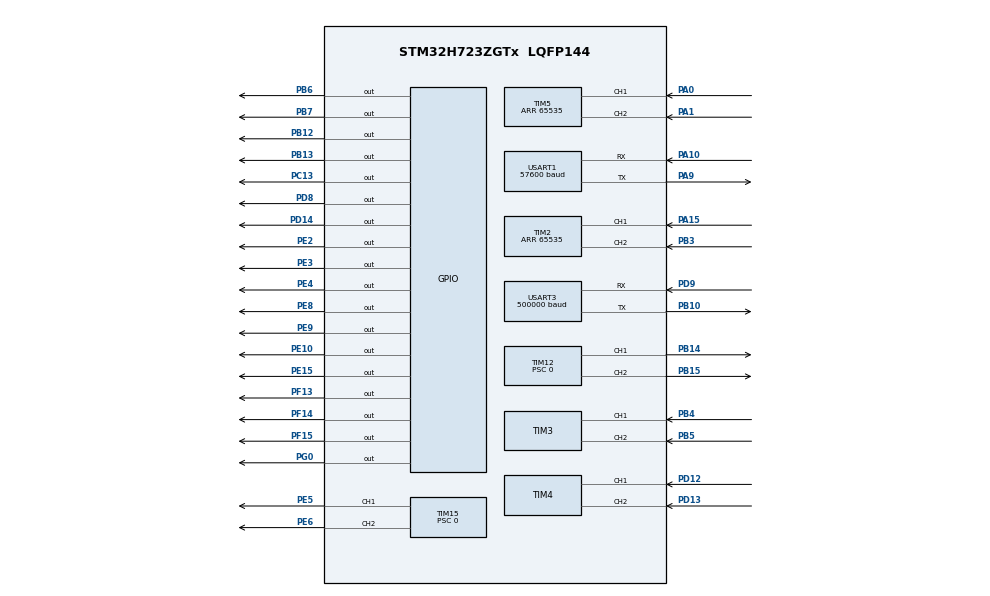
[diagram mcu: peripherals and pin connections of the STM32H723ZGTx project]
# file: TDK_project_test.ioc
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Dma.Request0=USART1_RX
Dma.Request1=USART1_TX
Dma.USART1_RX.0.Direction=DMA_PERIPH_TO_MEMORY
Dma.USART1_RX.0.EventEnable=DISABLE
Dma.USART1_RX.0.FIFOMode=DMA_FIFOMODE_DISABLE
Dma.USART1_RX.0.Instance=DMA1_Stream0
Dma.USART1_RX.0.MemDataAlignment=DMA_MDATAALIGN_BYTE
Dma.USART1_RX.0.MemInc=DMA_MINC_ENABLE
Dma.USART1_RX.0.Mode=DMA_CIRCULAR
Dma.USART1_RX.0.PeriphDataAlignment=DMA_PDATAALIGN_BYTE
Dma.USART1_RX.0.PeriphInc=DMA_PINC_DISABLE
Dma.USART1_RX.0.Polarity=HAL_DMAMUX_REQ_GEN_RISING
Dma.USART1_RX.0.Priority=DMA_PRIORITY_HIGH
Dma.USART1_RX.0.RequestNumber=1
Dma.USART1_RX.0.SignalID=NONE
Dma.USART1_RX.0.SyncEnable=DISABLE
Dma.USART1_RX.0.SyncPolarity=HAL_DMAMUX_SYNC_NO_EVENT
Dma.USART1_RX.0.SyncRequestNumber=1
Dma.USART1_RX.0.SyncSignalID=NONE
Dma.USART1_TX.1.Direction=DMA_MEMORY_TO_PERIPH
Dma.USART1_TX.1.EventEnable=DISABLE
Dma.USART1_TX.1.FIFOMode=DMA_FIFOMODE_DISABLE
Dma.USART1_TX.1.Instance=DMA1_Stream1
Dma.USART1_TX.1.MemDataAlignment=DMA_MDATAALIGN_BYTE
Dma.USART1_TX.1.MemInc=DMA_MINC_ENABLE
Dma.USART1_TX.1.Mode=DMA_NORMAL
Dma.USART1_TX.1.PeriphDataAlignment=DMA_PDATAALIGN_BYTE
Dma.USART1_TX.1.PeriphInc=DMA_PINC_DISABLE
Dma.USART1_TX.1.Polarity=HAL_DMAMUX_REQ_GEN_RISING
Dma.USART1_TX.1.Priority=DMA_PRIORITY_HIGH
Dma.USART1_TX.1.RequestNumber=1
Dma.USART1_TX.1.SignalID=NONE
Dma.USART1_TX.1.SyncEnable=DISABLE
Dma.USART1_TX.1.SyncPolarity=HAL_DMAMUX_SYNC_NO_EVENT
Dma.USART1_TX.1.SyncRequestNumber=1
Dma.USART1_TX.1.SyncSignalID=NONE
Mcu.Family=STM32H7
Mcu.Name=STM32H723ZGTx
Mcu.Package=LQFP144
NVIC.DMA1_Stream0_IRQn=true\:0\:0\:false\:false\:true\:false\:true\:true
NVIC.DMA1_Stream1_IRQn=true\:0\:0\:false\:false\:true\:false\:true\:true
NVIC.PriorityGroup=NVIC_PRIORITYGROUP_4
NVIC.TIM1_BRK_IRQn=true\:0\:0\:false\:false\:true\:true\:true\:true
NVIC.TIM1_CC_IRQn=true\:0\:0\:false\:false\:true\:true\:true\:true
NVIC.TIM1_TRG_COM_IRQn=true\:0\:0\:false\:false\:true\:true\:true\:true
NVIC.TIM1_UP_IRQn=true\:0\:0\:false\:false\:true\:true\:true\:true
NVIC.TIM23_IRQn=true\:0\:0\:false\:false\:true\:true\:true\:true
NVIC.TIM8_BRK_TIM12_IRQn=true\:0\:0\:false\:false\:true\:true\:true\:true
NVIC.TIM8_CC_IRQn=true\:0\:0\:false\:false\:true\:true\:true\:true
NVIC.TIM8_TRG_COM_TIM14_IRQn=true\:0\:0\:false\:false\:true\:true\:true\:true
NVIC.TIM8_UP_TIM13_IRQn=true\:0\:0\:false\:false\:true\:true\:true\:true
NVIC.USART1_IRQn=true\:0\:0\:false\:false\:true\:true\:true\:true
NVIC.USART3_IRQn=true\:0\:0\:false\:false\:true\:true\:true\:true
PA0.Signal=S_TIM5_CH1
PA1.Signal=S_TIM5_CH2
PA10.Mode=Asynchronous
PA10.Signal=USART1_RX
PA15(JTDI).Signal=S_TIM2_CH1_ETR
PA9.Mode=Asynchronous
PA9.Signal=USART1_TX
PB10.Mode=Asynchronous
PB10.Signal=USART3_TX
PB12.Signal=GPIO_Output
PB13.Signal=GPIO_Output
PB14.Signal=S_TIM12_CH1
PB15.Signal=S_TIM12_CH2
PB3(JTDO/TRACESWO).Signal=S_TIM2_CH2
PB4(NJTRST).Signal=S_TIM3_CH1
PB5.Signal=S_TIM3_CH2
PB6.Signal=GPIO_Output
PB7.Signal=GPIO_Output
PC13.Signal=GPIO_Output
PD12.Signal=S_TIM4_CH1
PD13.Signal=S_TIM4_CH2
PD14.Signal=GPIO_Output
PD8.Signal=GPIO_Output
PD9.Mode=Asynchronous
PD9.Signal=USART3_RX
PE10.Signal=GPIO_Output
PE15.Signal=GPIO_Output
PE2.Signal=GPIO_Output
PE3.Signal=GPIO_Output
PE4.Signal=GPIO_Output
PE5.Signal=S_TIM15_CH1
PE6.Signal=S_TIM15_CH2
PE8.Signal=GPIO_Output
PE9.Signal=GPIO_Output
PF13.Signal=GPIO_Output
PF14.Signal=GPIO_Output
PF15.Signal=GPIO_Output
PG0.Signal=GPIO_Output
PH0-OSC_IN.Mode=HSE-External-Oscillator
PH0-OSC_IN.Signal=RCC_OSC_IN
PH1-OSC_OUT.Mode=HSE-External-Oscillator
PH1-OSC_OUT.Signal=RCC_OSC_OUT
ProjectManager.HeapSize=0x200
ProjectManager.StackSize=0x400
ProjectManager.TargetToolchain=STM32CubeIDE
RCC.ADCFreq_Value=16125000
RCC.APB1Freq_Value=42000000
RCC.APB2Freq_Value=42000000
RCC.APB3Freq_Value=42000000
RCC.APB4Freq_Value=42000000
RCC.CortexFreq_Value=168000000
RCC.D1PPRE=RCC_APB3_DIV2
RCC.D2PPRE1=RCC_APB1_DIV2
RCC.D2PPRE2=RCC_APB2_DIV2
RCC.D3PPRE=RCC_APB4_DIV2
RCC.DIVM1=1
RCC.DIVN1=42
RCC.HCLKFreq_Value=84000000
RCC.HPRE=RCC_HCLK_DIV2
RCC.HSE_VALUE=8000000
RCC.PLLSourceVirtual=RCC_PLLSOURCE_HSE
RCC.SYSCLKFreq_VALUE=168000000
RCC.SYSCLKSource=RCC_SYSCLKSOURCE_PLLCLK
RCC.USBFreq_Value=168000000
SH.S_TIM12_CH1.0=TIM12_CH1,PWM Generation1 CH1
SH.S_TIM12_CH2.0=TIM12_CH2,PWM Generation2 CH2
SH.S_TIM15_CH1.0=TIM15_CH1,PWM Generation1 CH1
SH.S_TIM15_CH2.0=TIM15_CH2,PWM Generation2 CH2
SH.S_TIM2_CH1_ETR.0=TIM2_CH1,Encoder_Interface
SH.S_TIM2_CH2.0=TIM2_CH2,Encoder_Interface
SH.S_TIM3_CH1.0=TIM3_CH1,Encoder_Interface
SH.S_TIM3_CH2.0=TIM3_CH2,Encoder_Interface
SH.S_TIM4_CH1.0=TIM4_CH1,Encoder_Interface
SH.S_TIM4_CH2.0=TIM4_CH2,Encoder_Interface
SH.S_TIM5_CH1.0=TIM5_CH1,Encoder_Interface
SH.S_TIM5_CH2.0=TIM5_CH2,Encoder_Interface
TIM1.Period=3999
TIM1.Prescaler=83
TIM12.Channel-PWM\ Generation1\ CH1=TIM_CHANNEL_1
TIM12.Channel-PWM\ Generation2\ CH2=TIM_CHANNEL_2
TIM12.Period=999
TIM12.Prescaler=0
TIM15.Channel-PWM\ Generation1\ CH1=TIM_CHANNEL_1
TIM15.Channel-PWM\ Generation2\ CH2=TIM_CHANNEL_2
TIM15.Period=999
TIM15.Prescaler=0
TIM2.EncoderMode=TIM_ENCODERMODE_TI12
TIM2.Period=65535
TIM23.Period=9999
TIM23.Prescaler=83
TIM3.EncoderMode=TIM_ENCODERMODE_TI12
TIM4.EncoderMode=TIM_ENCODERMODE_TI12
TIM5.EncoderMode=TIM_ENCODERMODE_TI12
TIM5.Period=65535
TIM8.Period=999
TIM8.Prescaler=83
USART1.BaudRate=57600
USART1.VirtualMode-Asynchronous=VM_ASYNC
USART3.BaudRate=500000
USART3.VirtualMode-Asynchronous=VM_ASYNC
VP_TIM1_VS_ClockSourceINT.Mode=Internal
VP_TIM23_VS_ClockSourceINT.Mode=Internal
VP_TIM8_VS_ClockSourceINT.Mode=Internal
board=custom

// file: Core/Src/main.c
/* USER CODE BEGIN Header */
/**
  ******************************************************************************
  * @file           : main.c
  * @brief          : Main program body
  ******************************************************************************
  * @attention
  *
  * Copyright (c) 2023 STMicroelectronics.
  * All rights reserved.
  *
  * This software is licensed under terms that can be found in the LICENSE file
  * in the root directory of this software component.
  * If no LICENSE file comes with this software, it is provided AS-IS.
  *
  ******************************************************************************
  */
/* USER CODE END Header */
#include "main.h"

/* USER CODE BEGIN Includes */
#include "mainpp.h"
/* USER CODE END Includes */

TIM_HandleTypeDef htim1;
TIM_HandleTypeDef htim2;
TIM_HandleTypeDef htim3;
TIM_HandleTypeDef htim4;
TIM_HandleTypeDef htim5;
TIM_HandleTypeDef htim8;
TIM_HandleTypeDef htim12;
TIM_HandleTypeDef htim15;
TIM_HandleTypeDef htim23;

UART_HandleTypeDef huart1;
UART_HandleTypeDef huart3;
DMA_HandleTypeDef hdma_usart1_rx;
DMA_HandleTypeDef hdma_usart1_tx;

void SystemClock_Config(void);
static void MX_GPIO_Init(void);
static void MX_DMA_Init(void);
static void MX_TIM3_Init(void);
static void MX_TIM4_Init(void);
static void MX_TIM5_Init(void);
static void MX_TIM12_Init(void);
static void MX_TIM15_Init(void);
static void MX_TIM1_Init(void);
static void MX_TIM8_Init(void);
static void MX_TIM23_Init(void);
static void MX_USART1_UART_Init(void);
static void MX_TIM2_Init(void);
static void MX_USART3_UART_Init(void);
/* USER CODE BEGIN PFP */
int x = 0;
/* USER CODE END PFP */

int main(void)
{

  /* MCU Configuration--------------------------------------------------------*/

  /* Reset of all peripherals, Initializes the Flash interface and the Systick. */
  HAL_Init();

  /* Configure the system clock */
  SystemClock_Config();

  /* Initialize all configured peripherals */
  MX_GPIO_Init();
  MX_DMA_Init();
  MX_TIM3_Init();
  MX_TIM4_Init();
  MX_TIM5_Init();
  MX_TIM12_Init();
  MX_TIM15_Init();
  MX_TIM1_Init();
  MX_TIM8_Init();
  MX_TIM23_Init();
  MX_USART1_UART_Init();
  MX_TIM2_Init();
  MX_USART3_UART_Init();
  /* USER CODE BEGIN 2 */
  main_function();
  /* USER CODE END 2 */

  /* Infinite loop */
  while (1)
  {

  }
}

void SystemClock_Config(void)
{
  RCC_OscInitTypeDef RCC_OscInitStruct = {0};
  RCC_ClkInitTypeDef RCC_ClkInitStruct = {0};

  /** Supply configuration update enable
  */
  HAL_PWREx_ConfigSupply(PWR_LDO_SUPPLY);

  /** Configure the main internal regulator output voltage
  */
  __HAL_PWR_VOLTAGESCALING_CONFIG(PWR_REGULATOR_VOLTAGE_SCALE3);

  while(!__HAL_PWR_GET_FLAG(PWR_FLAG_VOSRDY)) {}

  /** Initializes the RCC Oscillators according to the specified parameters
  * in the RCC_OscInitTypeDef structure.
  */
  RCC_OscInitStruct.OscillatorType = RCC_OSCILLATORTYPE_HSE;
  RCC_OscInitStruct.HSEState = RCC_HSE_ON;
  RCC_OscInitStruct.PLL.PLLState = RCC_PLL_ON;
  RCC_OscInitStruct.PLL.PLLSource = RCC_PLLSOURCE_HSE;
  RCC_OscInitStruct.PLL.PLLM = 1;
  RCC_OscInitStruct.PLL.PLLN = 42;
  RCC_OscInitStruct.PLL.PLLP = 2;
  RCC_OscInitStruct.PLL.PLLQ = 2;
  RCC_OscInitStruct.PLL.PLLR = 2;
  RCC_OscInitStruct.PLL.PLLRGE = RCC_PLL1VCIRANGE_3;
  RCC_OscInitStruct.PLL.PLLVCOSEL = RCC_PLL1VCOWIDE;
  RCC_OscInitStruct.PLL.PLLFRACN = 0;
  if (HAL_RCC_OscConfig(&RCC_OscInitStruct) != HAL_OK)
  {
    Error_Handler();
  }

  /** Initializes the CPU, AHB and APB buses clocks
  */
  RCC_ClkInitStruct.ClockType = RCC_CLOCKTYPE_HCLK|RCC_CLOCKTYPE_SYSCLK
                              |RCC_CLOCKTYPE_PCLK1|RCC_CLOCKTYPE_PCLK2
                              |RCC_CLOCKTYPE_D3PCLK1|RCC_CLOCKTYPE_D1PCLK1;
  RCC_ClkInitStruct.SYSCLKSource = RCC_SYSCLKSOURCE_PLLCLK;
  RCC_ClkInitStruct.SYSCLKDivider = RCC_SYSCLK_DIV1;
  RCC_ClkInitStruct.AHBCLKDivider = RCC_HCLK_DIV2;
  RCC_ClkInitStruct.APB3CLKDivider = RCC_APB3_DIV2;
  RCC_ClkInitStruct.APB1CLKDivider = RCC_APB1_DIV2;
  RCC_ClkInitStruct.APB2CLKDivider = RCC_APB2_DIV2;
  RCC_ClkInitStruct.APB4CLKDivider = RCC_APB4_DIV2;

  if (HAL_RCC_ClockConfig(&RCC_ClkInitStruct, FLASH_LATENCY_2) != HAL_OK)
  {
    Error_Handler();
  }
}

static void MX_TIM1_Init(void)
{

  TIM_ClockConfigTypeDef sClockSourceConfig = {0};
  TIM_MasterConfigTypeDef sMasterConfig = {0};

  htim1.Instance = TIM1;
  htim1.Init.Prescaler = 83;
  htim1.Init.CounterMode = TIM_COUNTERMODE_UP;
  htim1.Init.Period = 3999;
  htim1.Init.ClockDivision = TIM_CLOCKDIVISION_DIV1;
  htim1.Init.RepetitionCounter = 0;
  htim1.Init.AutoReloadPreload = TIM_AUTORELOAD_PRELOAD_DISABLE;
  if (HAL_TIM_Base_Init(&htim1) != HAL_OK)
  {
    Error_Handler();
  }
  sClockSourceConfig.ClockSource = TIM_CLOCKSOURCE_INTERNAL;
  if (HAL_TIM_ConfigClockSource(&htim1, &sClockSourceConfig) != HAL_OK)
  {
    Error_Handler();
  }
  sMasterConfig.MasterOutputTrigger = TIM_TRGO_RESET;
  sMasterConfig.MasterOutputTrigger2 = TIM_TRGO2_RESET;
  sMasterConfig.MasterSlaveMode = TIM_MASTERSLAVEMODE_DISABLE;
  if (HAL_TIMEx_MasterConfigSynchronization(&htim1, &sMasterConfig) != HAL_OK)
  {
    Error_Handler();
  }

}

static void MX_TIM2_Init(void)
{

  TIM_Encoder_InitTypeDef sConfig = {0};
  TIM_MasterConfigTypeDef sMasterConfig = {0};

  htim2.Instance = TIM2;
  htim2.Init.Prescaler = 0;
  htim2.Init.CounterMode = TIM_COUNTERMODE_UP;
  htim2.Init.Period = 65535;
  htim2.Init.ClockDivision = TIM_CLOCKDIVISION_DIV1;
  htim2.Init.AutoReloadPreload = TIM_AUTORELOAD_PRELOAD_DISABLE;
  sConfig.EncoderMode = TIM_ENCODERMODE_TI12;
  sConfig.IC1Polarity = TIM_ICPOLARITY_RISING;
  sConfig.IC1Selection = TIM_ICSELECTION_DIRECTTI;
  sConfig.IC1Prescaler = TIM_ICPSC_DIV1;
  sConfig.IC1Filter = 0;
  sConfig.IC2Polarity = TIM_ICPOLARITY_RISING;
  sConfig.IC2Selection = TIM_ICSELECTION_DIRECTTI;
  sConfig.IC2Prescaler = TIM_ICPSC_DIV1;
  sConfig.IC2Filter = 0;
  if (HAL_TIM_Encoder_Init(&htim2, &sConfig) != HAL_OK)
  {
    Error_Handler();
  }
  sMasterConfig.MasterOutputTrigger = TIM_TRGO_RESET;
  sMasterConfig.MasterSlaveMode = TIM_MASTERSLAVEMODE_DISABLE;
  if (HAL_TIMEx_MasterConfigSynchronization(&htim2, &sMasterConfig) != HAL_OK)
  {
    Error_Handler();
  }

}

static void MX_TIM3_Init(void)
{

  TIM_Encoder_InitTypeDef sConfig = {0};
  TIM_MasterConfigTypeDef sMasterConfig = {0};

  htim3.Instance = TIM3;
  htim3.Init.Prescaler = 0;
  htim3.Init.CounterMode = TIM_COUNTERMODE_UP;
  htim3.Init.Period = 65535;
  htim3.Init.ClockDivision = TIM_CLOCKDIVISION_DIV1;
  htim3.Init.AutoReloadPreload = TIM_AUTORELOAD_PRELOAD_DISABLE;
  sConfig.EncoderMode = TIM_ENCODERMODE_TI12;
  sConfig.IC1Polarity = TIM_ICPOLARITY_RISING;
  sConfig.IC1Selection = TIM_ICSELECTION_DIRECTTI;
  sConfig.IC1Prescaler = TIM_ICPSC_DIV1;
  sConfig.IC1Filter = 0;
  sConfig.IC2Polarity = TIM_ICPOLARITY_RISING;
  sConfig.IC2Selection = TIM_ICSELECTION_DIRECTTI;
  sConfig.IC2Prescaler = TIM_ICPSC_DIV1;
  sConfig.IC2Filter = 0;
  if (HAL_TIM_Encoder_Init(&htim3, &sConfig) != HAL_OK)
  {
    Error_Handler();
  }
  sMasterConfig.MasterOutputTrigger = TIM_TRGO_RESET;
  sMasterConfig.MasterSlaveMode = TIM_MASTERSLAVEMODE_DISABLE;
  if (HAL_TIMEx_MasterConfigSynchronization(&htim3, &sMasterConfig) != HAL_OK)
  {
    Error_Handler();
  }

}

static void MX_TIM4_Init(void)
{

  TIM_Encoder_InitTypeDef sConfig = {0};
  TIM_MasterConfigTypeDef sMasterConfig = {0};

  htim4.Instance = TIM4;
  htim4.Init.Prescaler = 0;
  htim4.Init.CounterMode = TIM_COUNTERMODE_UP;
  htim4.Init.Period = 65535;
  htim4.Init.ClockDivision = TIM_CLOCKDIVISION_DIV1;
  htim4.Init.AutoReloadPreload = TIM_AUTORELOAD_PRELOAD_DISABLE;
  sConfig.EncoderMode = TIM_ENCODERMODE_TI12;
  sConfig.IC1Polarity = TIM_ICPOLARITY_RISING;
  sConfig.IC1Selection = TIM_ICSELECTION_DIRECTTI;
  sConfig.IC1Prescaler = TIM_ICPSC_DIV1;
  sConfig.IC1Filter = 0;
  sConfig.IC2Polarity = TIM_ICPOLARITY_RISING;
  sConfig.IC2Selection = TIM_ICSELECTION_DIRECTTI;
  sConfig.IC2Prescaler = TIM_ICPSC_DIV1;
  sConfig.IC2Filter = 0;
  if (HAL_TIM_Encoder_Init(&htim4, &sConfig) != HAL_OK)
  {
    Error_Handler();
  }
  sMasterConfig.MasterOutputTrigger = TIM_TRGO_RESET;
  sMasterConfig.MasterSlaveMode = TIM_MASTERSLAVEMODE_DISABLE;
  if (HAL_TIMEx_MasterConfigSynchronization(&htim4, &sMasterConfig) != HAL_OK)
  {
    Error_Handler();
  }

}

static void MX_TIM5_Init(void)
{

  TIM_Encoder_InitTypeDef sConfig = {0};
  TIM_MasterConfigTypeDef sMasterConfig = {0};

  htim5.Instance = TIM5;
  htim5.Init.Prescaler = 0;
  htim5.Init.CounterMode = TIM_COUNTERMODE_UP;
  htim5.Init.Period = 65535;
  htim5.Init.ClockDivision = TIM_CLOCKDIVISION_DIV1;
  htim5.Init.AutoReloadPreload = TIM_AUTORELOAD_PRELOAD_DISABLE;
  sConfig.EncoderMode = TIM_ENCODERMODE_TI12;
  sConfig.IC1Polarity = TIM_ICPOLARITY_RISING;
  sConfig.IC1Selection = TIM_ICSELECTION_DIRECTTI;
  sConfig.IC1Prescaler = TIM_ICPSC_DIV1;
  sConfig.IC1Filter = 0;
  sConfig.IC2Polarity = TIM_ICPOLARITY_RISING;
  sConfig.IC2Selection = TIM_ICSELECTION_DIRECTTI;
  sConfig.IC2Prescaler = TIM_ICPSC_DIV1;
  sConfig.IC2Filter = 0;
  if (HAL_TIM_Encoder_Init(&htim5, &sConfig) != HAL_OK)
  {
    Error_Handler();
  }
  sMasterConfig.MasterOutputTrigger = TIM_TRGO_RESET;
  sMasterConfig.MasterSlaveMode = TIM_MASTERSLAVEMODE_DISABLE;
  if (HAL_TIMEx_MasterConfigSynchronization(&htim5, &sMasterConfig) != HAL_OK)
  {
    Error_Handler();
  }

}

static void MX_TIM8_Init(void)
{

  TIM_ClockConfigTypeDef sClockSourceConfig = {0};
  TIM_MasterConfigTypeDef sMasterConfig = {0};

  htim8.Instance = TIM8;
  htim8.Init.Prescaler = 83;
  htim8.Init.CounterMode = TIM_COUNTERMODE_UP;
  htim8.Init.Period = 999;
  htim8.Init.ClockDivision = TIM_CLOCKDIVISION_DIV1;
  htim8.Init.RepetitionCounter = 0;
  htim8.Init.AutoReloadPreload = TIM_AUTORELOAD_PRELOAD_DISABLE;
  if (HAL_TIM_Base_Init(&htim8) != HAL_OK)
  {
    Error_Handler();
  }
  sClockSourceConfig.ClockSource = TIM_CLOCKSOURCE_INTERNAL;
  if (HAL_TIM_ConfigClockSource(&htim8, &sClockSourceConfig) != HAL_OK)
  {
    Error_Handler();
  }
  sMasterConfig.MasterOutputTrigger = TIM_TRGO_RESET;
  sMasterConfig.MasterOutputTrigger2 = TIM_TRGO2_RESET;
  sMasterConfig.MasterSlaveMode = TIM_MASTERSLAVEMODE_DISABLE;
  if (HAL_TIMEx_MasterConfigSynchronization(&htim8, &sMasterConfig) != HAL_OK)
  {
    Error_Handler();
  }

}

static void MX_TIM12_Init(void)
{

  TIM_MasterConfigTypeDef sMasterConfig = {0};
  TIM_OC_InitTypeDef sConfigOC = {0};

  htim12.Instance = TIM12;
  htim12.Init.Prescaler = 0;
  htim12.Init.CounterMode = TIM_COUNTERMODE_UP;
  htim12.Init.Period = 999;
  htim12.Init.ClockDivision = TIM_CLOCKDIVISION_DIV1;
  htim12.Init.AutoReloadPreload = TIM_AUTORELOAD_PRELOAD_DISABLE;
  if (HAL_TIM_PWM_Init(&htim12) != HAL_OK)
  {
    Error_Handler();
  }
  sMasterConfig.MasterOutputTrigger = TIM_TRGO_RESET;
  sMasterConfig.MasterSlaveMode = TIM_MASTERSLAVEMODE_DISABLE;
  if (HAL_TIMEx_MasterConfigSynchronization(&htim12, &sMasterConfig) != HAL_OK)
  {
    Error_Handler();
  }
  sConfigOC.OCMode = TIM_OCMODE_PWM1;
  sConfigOC.Pulse = 0;
  sConfigOC.OCPolarity = TIM_OCPOLARITY_HIGH;
  sConfigOC.OCFastMode = TIM_OCFAST_DISABLE;
  if (HAL_TIM_PWM_ConfigChannel(&htim12, &sConfigOC, TIM_CHANNEL_1) != HAL_OK)
  {
    Error_Handler();
  }
  if (HAL_TIM_PWM_ConfigChannel(&htim12, &sConfigOC, TIM_CHANNEL_2) != HAL_OK)
  {
    Error_Handler();
  }
  HAL_TIM_MspPostInit(&htim12);

}

static void MX_TIM15_Init(void)
{

  TIM_MasterConfigTypeDef sMasterConfig = {0};
  TIM_OC_InitTypeDef sConfigOC = {0};
  TIM_BreakDeadTimeConfigTypeDef sBreakDeadTimeConfig = {0};

  htim15.Instance = TIM15;
  htim15.Init.Prescaler = 0;
  htim15.Init.CounterMode = TIM_COUNTERMODE_UP;
  htim15.Init.Period = 999;
  htim15.Init.ClockDivision = TIM_CLOCKDIVISION_DIV1;
  htim15.Init.RepetitionCounter = 0;
  htim15.Init.AutoReloadPreload = TIM_AUTORELOAD_PRELOAD_DISABLE;
  if (HAL_TIM_PWM_Init(&htim15) != HAL_OK)
  {
    Error_Handler();
  }
  sMasterConfig.MasterOutputTrigger = TIM_TRGO_RESET;
  sMasterConfig.MasterSlaveMode = TIM_MASTERSLAVEMODE_DISABLE;
  if (HAL_TIMEx_MasterConfigSynchronization(&htim15, &sMasterConfig) != HAL_OK)
  {
    Error_Handler();
  }
  sConfigOC.OCMode = TIM_OCMODE_PWM1;
  sConfigOC.Pulse = 0;
  sConfigOC.OCPolarity = TIM_OCPOLARITY_HIGH;
  sConfigOC.OCNPolarity = TIM_OCNPOLARITY_HIGH;
  sConfigOC.OCFastMode = TIM_OCFAST_DISABLE;
  sConfigOC.OCIdleState = TIM_OCIDLESTATE_RESET;
  sConfigOC.OCNIdleState = TIM_OCNIDLESTATE_RESET;
  if (HAL_TIM_PWM_ConfigChannel(&htim15, &sConfigOC, TIM_CHANNEL_1) != HAL_OK)
  {
    Error_Handler();
  }
  if (HAL_TIM_PWM_ConfigChannel(&htim15, &sConfigOC, TIM_CHANNEL_2) != HAL_OK)
  {
    Error_Handler();
  }
  sBreakDeadTimeConfig.OffStateRunMode = TIM_OSSR_DISABLE;
  sBreakDeadTimeConfig.OffStateIDLEMode = TIM_OSSI_DISABLE;
  sBreakDeadTimeConfig.LockLevel = TIM_LOCKLEVEL_OFF;
  sBreakDeadTimeConfig.DeadTime = 0;
  sBreakDeadTimeConfig.BreakState = TIM_BREAK_DISABLE;
  sBreakDeadTimeConfig.BreakPolarity = TIM_BREAKPOLARITY_HIGH;
  sBreakDeadTimeConfig.BreakFilter = 0;
  sBreakDeadTimeConfig.AutomaticOutput = TIM_AUTOMATICOUTPUT_DISABLE;
  if (HAL_TIMEx_ConfigBreakDeadTime(&htim15, &sBreakDeadTimeConfig) != HAL_OK)
  {
    Error_Handler();
  }
  HAL_TIM_MspPostInit(&htim15);

}

static void MX_TIM23_Init(void)
{

  TIM_ClockConfigTypeDef sClockSourceConfig = {0};
  TIM_MasterConfigTypeDef sMasterConfig = {0};

  htim23.Instance = TIM23;
  htim23.Init.Prescaler = 83;
  htim23.Init.CounterMode = TIM_COUNTERMODE_UP;
  htim23.Init.Period = 9999;
  htim23.Init.ClockDivision = TIM_CLOCKDIVISION_DIV1;
  htim23.Init.AutoReloadPreload = TIM_AUTORELOAD_PRELOAD_DISABLE;
  if (HAL_TIM_Base_Init(&htim23) != HAL_OK)
  {
    Error_Handler();
  }
  sClockSourceConfig.ClockSource = TIM_CLOCKSOURCE_INTERNAL;
  if (HAL_TIM_ConfigClockSource(&htim23, &sClockSourceConfig) != HAL_OK)
  {
    Error_Handler();
  }
  sMasterConfig.MasterOutputTrigger = TIM_TRGO_RESET;
  sMasterConfig.MasterSlaveMode = TIM_MASTERSLAVEMODE_DISABLE;
  if (HAL_TIMEx_MasterConfigSynchronization(&htim23, &sMasterConfig) != HAL_OK)
  {
    Error_Handler();
  }

}

static void MX_USART1_UART_Init(void)
{

  huart1.Instance = USART1;
  huart1.Init.BaudRate = 57600;
  huart1.Init.WordLength = UART_WORDLENGTH_8B;
  huart1.Init.StopBits = UART_STOPBITS_1;
  huart1.Init.Parity = UART_PARITY_NONE;
  huart1.Init.Mode = UART_MODE_TX_RX;
  huart1.Init.HwFlowCtl = UART_HWCONTROL_NONE;
  huart1.Init.OverSampling = UART_OVERSAMPLING_16;
  huart1.Init.OneBitSampling = UART_ONE_BIT_SAMPLE_DISABLE;
  huart1.Init.ClockPrescaler = UART_PRESCALER_DIV1;
  huart1.AdvancedInit.AdvFeatureInit = UART_ADVFEATURE_NO_INIT;
  if (HAL_UART_Init(&huart1) != HAL_OK)
  {
    Error_Handler();
  }
  if (HAL_UARTEx_SetTxFifoThreshold(&huart1, UART_TXFIFO_THRESHOLD_1_8) != HAL_OK)
  {
    Error_Handler();
  }
  if (HAL_UARTEx_SetRxFifoThreshold(&huart1, UART_RXFIFO_THRESHOLD_1_8) != HAL_OK)
  {
    Error_Handler();
  }
  if (HAL_UARTEx_DisableFifoMode(&huart1) != HAL_OK)
  {
    Error_Handler();
  }

}

static void MX_USART3_UART_Init(void)
{

  huart3.Instance = USART3;
  huart3.Init.BaudRate = 500000;
  huart3.Init.WordLength = UART_WORDLENGTH_8B;
  huart3.Init.StopBits = UART_STOPBITS_1;
  huart3.Init.Parity = UART_PARITY_NONE;
  huart3.Init.Mode = UART_MODE_TX_RX;
  huart3.Init.HwFlowCtl = UART_HWCONTROL_NONE;
  huart3.Init.OverSampling = UART_OVERSAMPLING_16;
  huart3.Init.OneBitSampling = UART_ONE_BIT_SAMPLE_DISABLE;
  huart3.Init.ClockPrescaler = UART_PRESCALER_DIV1;
  huart3.AdvancedInit.AdvFeatureInit = UART_ADVFEATURE_NO_INIT;
  if (HAL_UART_Init(&huart3) != HAL_OK)
  {
    Error_Handler();
  }
  if (HAL_UARTEx_SetTxFifoThreshold(&huart3, UART_TXFIFO_THRESHOLD_1_8) != HAL_OK)
  {
    Error_Handler();
  }
  if (HAL_UARTEx_SetRxFifoThreshold(&huart3, UART_RXFIFO_THRESHOLD_1_8) != HAL_OK)
  {
    Error_Handler();
  }
  if (HAL_UARTEx_DisableFifoMode(&huart3) != HAL_OK)
  {
    Error_Handler();
  }

}

static void MX_DMA_Init(void)
{

  /* DMA controller clock enable */
  __HAL_RCC_DMA1_CLK_ENABLE();

  /* DMA interrupt init */
  /* DMA1_Stream0_IRQn interrupt configuration */
  HAL_NVIC_SetPriority(DMA1_Stream0_IRQn, 0, 0);
  HAL_NVIC_EnableIRQ(DMA1_Stream0_IRQn);
  /* DMA1_Stream1_IRQn interrupt configuration */
  HAL_NVIC_SetPriority(DMA1_Stream1_IRQn, 0, 0);
  HAL_NVIC_EnableIRQ(DMA1_Stream1_IRQn);

}

static void MX_GPIO_Init(void)
{
  GPIO_InitTypeDef GPIO_InitStruct = {0};

  /* GPIO Ports Clock Enable */
  __HAL_RCC_GPIOE_CLK_ENABLE();
  __HAL_RCC_GPIOC_CLK_ENABLE();
  __HAL_RCC_GPIOH_CLK_ENABLE();
  __HAL_RCC_GPIOA_CLK_ENABLE();
  __HAL_RCC_GPIOF_CLK_ENABLE();
  __HAL_RCC_GPIOG_CLK_ENABLE();
  __HAL_RCC_GPIOB_CLK_ENABLE();
  __HAL_RCC_GPIOD_CLK_ENABLE();

  /*Configure GPIO pin Output Level */
  HAL_GPIO_WritePin(GPIOE, GPIO_PIN_2|GPIO_PIN_3|GPIO_PIN_4|GPIO_PIN_8
                          |GPIO_PIN_9|GPIO_PIN_10|GPIO_PIN_15, GPIO_PIN_RESET);

  /*Configure GPIO pin Output Level */
  HAL_GPIO_WritePin(GPIOC, GPIO_PIN_13, GPIO_PIN_RESET);

  /*Configure GPIO pin Output Level */
  HAL_GPIO_WritePin(GPIOF, GPIO_PIN_13|GPIO_PIN_14|GPIO_PIN_15, GPIO_PIN_RESET);

  /*Configure GPIO pin Output Level */
  HAL_GPIO_WritePin(GPIOG, GPIO_PIN_0, GPIO_PIN_RESET);

  /*Configure GPIO pin Output Level */
  HAL_GPIO_WritePin(GPIOB, GPIO_PIN_12|GPIO_PIN_13|GPIO_PIN_6|GPIO_PIN_7, GPIO_PIN_RESET);

  /*Configure GPIO pin Output Level */
  HAL_GPIO_WritePin(GPIOD, GPIO_PIN_8|GPIO_PIN_14, GPIO_PIN_RESET);

  /*Configure GPIO pins : PE2 PE3 PE4 PE8
                           PE9 PE10 PE15 */
  GPIO_InitStruct.Pin = GPIO_PIN_2|GPIO_PIN_3|GPIO_PIN_4|GPIO_PIN_8
                          |GPIO_PIN_9|GPIO_PIN_10|GPIO_PIN_15;
  GPIO_InitStruct.Mode = GPIO_MODE_OUTPUT_PP;
  GPIO_InitStruct.Pull = GPIO_NOPULL;
  GPIO_InitStruct.Speed = GPIO_SPEED_FREQ_LOW;
  HAL_GPIO_Init(GPIOE, &GPIO_InitStruct);

  /*Configure GPIO pin : PC13 */
  GPIO_InitStruct.Pin = GPIO_PIN_13;
  GPIO_InitStruct.Mode = GPIO_MODE_OUTPUT_PP;
  GPIO_InitStruct.Pull = GPIO_NOPULL;
  GPIO_InitStruct.Speed = GPIO_SPEED_FREQ_LOW;
  HAL_GPIO_Init(GPIOC, &GPIO_InitStruct);

  /*Configure GPIO pins : PF13 PF14 PF15 */
  GPIO_InitStruct.Pin = GPIO_PIN_13|GPIO_PIN_14|GPIO_PIN_15;
  GPIO_InitStruct.Mode = GPIO_MODE_OUTPUT_PP;
  GPIO_InitStruct.Pull = GPIO_NOPULL;
  GPIO_InitStruct.Speed = GPIO_SPEED_FREQ_LOW;
  HAL_GPIO_Init(GPIOF, &GPIO_InitStruct);

  /*Configure GPIO pin : PG0 */
  GPIO_InitStruct.Pin = GPIO_PIN_0;
  GPIO_InitStruct.Mode = GPIO_MODE_OUTPUT_PP;
  GPIO_InitStruct.Pull = GPIO_NOPULL;
  GPIO_InitStruct.Speed = GPIO_SPEED_FREQ_LOW;
  HAL_GPIO_Init(GPIOG, &GPIO_InitStruct);

  /*Configure GPIO pins : PB12 PB13 PB6 PB7 */
  GPIO_InitStruct.Pin = GPIO_PIN_12|GPIO_PIN_13|GPIO_PIN_6|GPIO_PIN_7;
  GPIO_InitStruct.Mode = GPIO_MODE_OUTPUT_PP;
  GPIO_InitStruct.Pull = GPIO_NOPULL;
  GPIO_InitStruct.Speed = GPIO_SPEED_FREQ_LOW;
  HAL_GPIO_Init(GPIOB, &GPIO_InitStruct);

  /*Configure GPIO pins : PD8 PD14 */
  GPIO_InitStruct.Pin = GPIO_PIN_8|GPIO_PIN_14;
  GPIO_InitStruct.Mode = GPIO_MODE_OUTPUT_PP;
  GPIO_InitStruct.Pull = GPIO_NOPULL;
  GPIO_InitStruct.Speed = GPIO_SPEED_FREQ_LOW;
  HAL_GPIO_Init(GPIOD, &GPIO_InitStruct);

}

void Error_Handler(void)
{
  __disable_irq();
  while (1)
  {
  }
}
